# AT32F435xx_v2 register map
Vendor: Keil; Series: AT32F435; File version: 1.0
CPU: CM4 r0p1, little endian, no MPU, FPU, 4 interrupt priority bits
Registers are 32-bit, read-write, reset 0x0 unless marked. A register's access mark holds for its fields unless they carry their own. Offsets are from the block's base; [hi:lo] are bit positions; {n}, {i} and the like mark numbered series; 'fields as' and 'values as' point back to an identical list.

## TMR1 — Advanced timer
Base 0x40010000
Same registers: TMR8 0x40010400, TMR20 0x40014C00
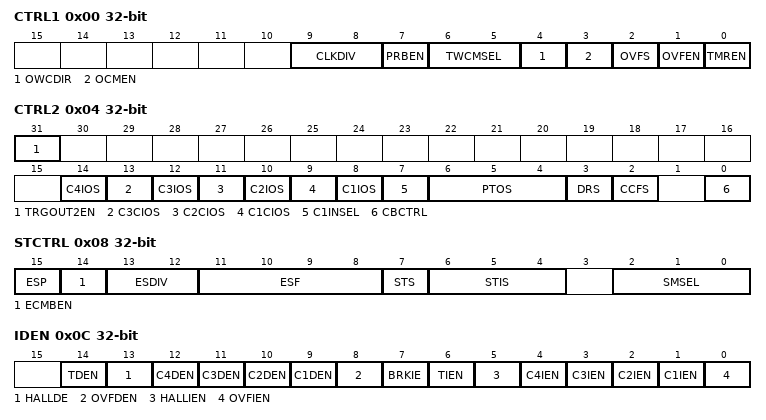
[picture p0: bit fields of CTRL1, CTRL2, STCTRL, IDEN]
0x00 CTRL1 — Control register 1
  [9:8] CLKDIV — Clock divider
  [7] PRBEN — Period buffer enable
  [6:5] TWCMSEL — Two-way count mode selection
  [4] OWCDIR — One-way count direction
  [3] OCMEN — One cycle mode enable
  [2] OVFS — Overflow event source
  [1] OVFEN — Overflow event enable
  [0] TMREN — TMR enable
0x04 CTRL2 — Control register 2
  [31] TRGOUT2EN — TRGOUT2 enable
  [2n+6] C{n}IOS (n=1..4) — Channel {n} idle output state
  [13] C3CIOS — Channel 3 complementary idle output state
  [11] C2CIOS — Channel 2 complementary idle output state
  [9] C1CIOS — Channel 1 complementary idle output state
  [7] C1INSEL — C1IN selection
  [6:4] PTOS — Primary TMR output selection
  [3] DRS — DMA request source
  [2] CCFS — Channel control bit flash select
  [0] CBCTRL — Channel buffer control
0x08 STCTRL — Subordinate TMR control register
  [15] ESP — External signal polarity
  [14] ECMBEN — External clock mode B enable
  [13:12] ESDIV — External signal divider
  [11:8] ESF — External signal filter
  [7] STS — Subordinate TMR synchronization
  [6:4] STIS — Subordinate TMR input selection
  [2:0] SMSEL — Subordinate TMR mode selection
0x0C IDEN — Interrupt/DMA enable register
  [14] TDEN — Trigger DMA request enable
  [13] HALLDE — HALL DMA request enable
  [n+8] C{n}DEN (n=1..4) — Channel {n} DMA request enable
  [8] OVFDEN — Overflow DMA request enable
  [7] BRKIE — Brake interrupt enable
  [6] TIEN — Trigger interrupt enable
  [5] HALLIEN — HALL interrupt enable
  [n] C{n}IEN (n=1..4) — Channel {n} interrupt enable
  [0] OVFIEN — Overflow interrupt enable
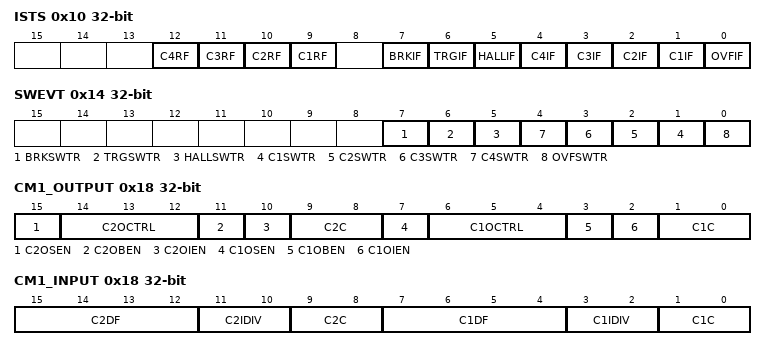
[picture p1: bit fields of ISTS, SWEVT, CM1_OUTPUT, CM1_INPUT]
0x10 ISTS — Interrupt status register
  [n+8] C{n}RF (n=1..4) — Channel {n} recapture flag
  [7] BRKIF — Brake interrupt flag
  [6] TRGIF — Trigger interrupt flag
  [5] HALLIF — HALL interrupt flag
  [n] C{n}IF (n=1..4) — Channel {n} interrupt flag
  [0] OVFIF — Overflow interrupt flag
0x14 SWEVT — Software event register
  [7] BRKSWTR — Brake event triggered by software
  [6] TRGSWTR — Trigger event triggered by software
  [5] HALLSWTR — HALL event triggered by software
  [n] C{n}SWTR (n=1..4) — Channel {n} event triggered by software
  [0] OVFSWTR — Overflow event triggered by software
0x18 CM1_OUTPUT — Channel output mode register
  [15] C2OSEN — Channel 2 output switch enable
  [14:12] C2OCTRL — Channel 2 output control
  [11] C2OBEN — Channel 2 output buffer enable
  [10] C2OIEN — Channel 2 output immediately enable
  [9:8] C2C — Channel 2 configure
  [7] C1OSEN — Channel 1 output switch enable
  [6:4] C1OCTRL — Channel 1 output control
  [3] C1OBEN — Channel 1 output buffer enable
  [2] C1OIEN — Channel 1 output immediately enable
  [1:0] C1C — Channel 1 configure
0x18 CM1_INPUT (alternate view of CM1_OUTPUT) — Channel input mode register 1
  [15:12] C2DF — Channel 2 digital filter
  [11:10] C2IDIV — Channel 2 input divider
  [9:8] C2C — Channel 2 configure
  [7:4] C1DF — Channel 1 digital filter
  [3:2] C1IDIV — Channel 1 input divider
  [1:0] C1C — Channel 1 configure
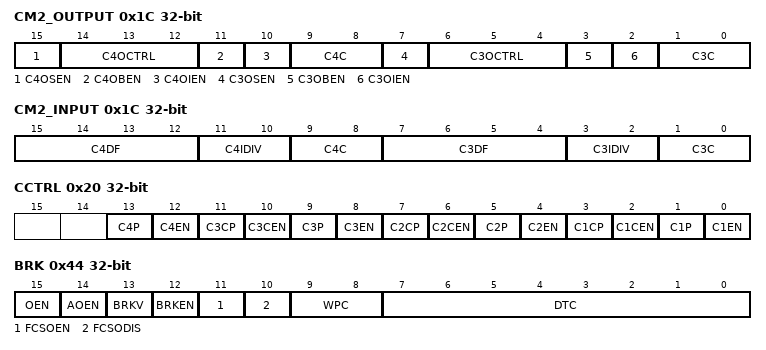
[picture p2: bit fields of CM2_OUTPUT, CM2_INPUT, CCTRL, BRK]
0x1C CM2_OUTPUT — Channel output mode register 2
  [15] C4OSEN — Channel 4 output switch enable
  [14:12] C4OCTRL — Channel 4 output control
  [11] C4OBEN — Channel 4 output buffer enable
  [10] C4OIEN — Channel 4 output immediately enable
  [9:8] C4C — Channel 4 configure
  [7] C3OSEN — Channel 3 output switch enable
  [6:4] C3OCTRL — Channel 3 output control
  [3] C3OBEN — Channel 3 output buffer enable
  [2] C3OIEN — Channel 3 output immediately enable
  [1:0] C3C — Channel 3 configure
0x1C CM2_INPUT (alternate view of CM2_OUTPUT) — Channel input mode register 2
  [15:12] C4DF — Channel 4 digital filter
  [11:10] C4IDIV — Channel 4 input divider
  [9:8] C4C — Channel 4 configure
  [7:4] C3DF — Channel 3 digital filter
  [3:2] C3IDIV — Channel 3 input divider
  [1:0] C3C — Channel 3 configure
0x20 CCTRL — Channel control register
  [4n-3] C{n}P (n=1..4) — Channel {n} Polarity
  [4n-4] C{n}EN (n=1..4) — Channel {n} enable
  [11] C3CP — Channel 3 complementary polarity
  [10] C3CEN — Channel 3 complementary enable
  [7] C2CP — Channel 2 complementary polarity
  [6] C2CEN — Channel 2 complementary enable
  [3] C1CP — Channel 1 complementary polarity
  [2] C1CEN — Channel 1 complementary enable
0x24 CVAL — Counter value
  [15:0] CVAL
0x28 DIV — Divider value
  [15:0] DIV
0x2C PR — Period value
  [15:0] PR
0x30 RPR — Repetition of period value
  [7:0] RPR
{0x30+4i} C{i}DT (i=1..4) — Channel {i} data register
  [15:0] C{i}DT
0x44 BRK — Brake register
  [15] OEN — Output enable
  [14] AOEN — Automatic output enable
  [13] BRKV — Brake input validity
  [12] BRKEN — Brake enable
  [11] FCSOEN — Frozen channel status when holistic output enable
  [10] FCSODIS — Frozen channel status when holistic output disable
  [9:8] WPC — Write protected configuration
  [7:0] DTC — Dead-time configuration
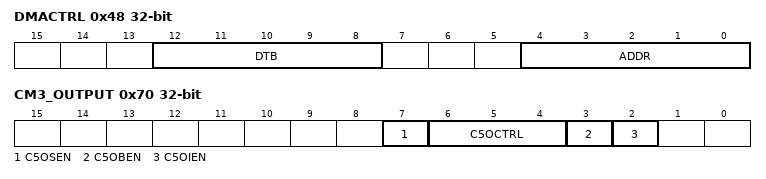
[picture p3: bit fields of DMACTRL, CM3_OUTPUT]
0x48 DMACTRL — DMA control register
  [12:8] DTB — DMA transfer bytes
  [4:0] ADDR — DMA transfer address offset
0x4C DMADT — DMA data register
  [15:0] DMADT
0x70 CM3_OUTPUT — Channel output mode register
  [7] C5OSEN — Channel 5 output switch enable
  [6:4] C5OCTRL — Channel 5 output control
  [3] C5OBEN — Channel 5 output buffer enable
  [2] C5OIEN — Channel 5 output immediately enable
0x74 C5DT — Channel 5 data register
  [15:0] C5DT

## TMR2 — General purpose timer
Base 0x40000000
Registers as TMR1, without RPR, BRK, CM3_OUTPUT, C5DT; these are added or differ:
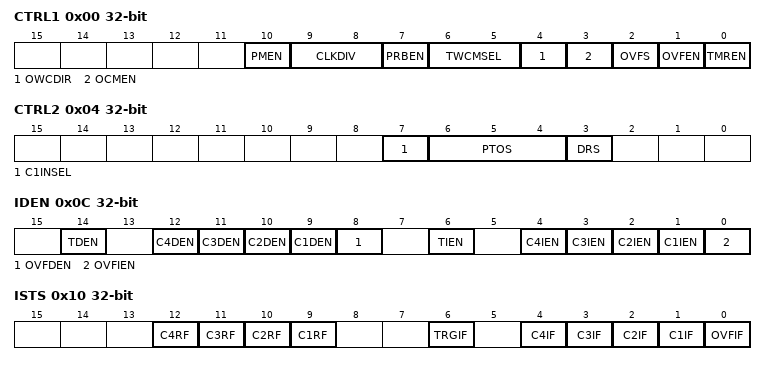
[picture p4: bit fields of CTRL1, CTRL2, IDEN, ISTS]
0x00 CTRL1 — Control register 1
  [10] PMEN — Plus Mode Enable
  [9:8] CLKDIV — Clock divider
  [7] PRBEN — Period buffer enable
  [6:5] TWCMSEL — Two-way count mode selection
  [4] OWCDIR — One-way count direction
  [3] OCMEN — One cycle mode enable
  [2] OVFS — Overflow event source
  [1] OVFEN — Overflow event enable
  [0] TMREN — TMR enable
0x04 CTRL2 — Control register 2
  [7] C1INSEL — C1IN selection
  [6:4] PTOS — Primary TMR output selection
  [3] DRS — DMA request source
0x0C IDEN — Interrupt/DMA enable register
  [14] TDEN — Trigger DMA request enable
  [n+8] C{n}DEN (n=1..4) — Channel {n} DMA request enable
  [8] OVFDEN — Overflow DMA request enable
  [6] TIEN — Trigger interrupt enable
  [n] C{n}IEN (n=1..4) — Channel {n} interrupt enable
  [0] OVFIEN — Overflow interrupt enable
0x10 ISTS — Interrupt status register
  [n+8] C{n}RF (n=1..4) — Channel {n} recapture flag
  [6] TRGIF — Trigger interrupt flag
  [n] C{n}IF (n=1..4) — Channel {n} interrupt flag
  [0] OVFIF — Overflow interrupt flag
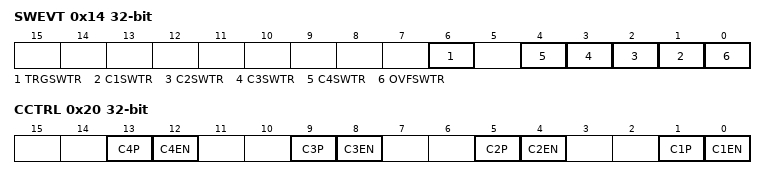
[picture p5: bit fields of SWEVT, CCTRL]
0x14 SWEVT — Software event register
  [6] TRGSWTR — Trigger event triggered by software
  [n] C{n}SWTR (n=1..4) — Channel {n} event triggered by software
  [0] OVFSWTR — Overflow event triggered by software
0x20 CCTRL — Channel control register
  [4n-3] C{n}P (n=1..4) — Channel {n} Polarity
  [4n-4] C{n}EN (n=1..4) — Channel {n} enable
0x24 CVAL — Counter value
0x2C PR — Period value
{0x30+4i} C{i}DT (i=1..4) — Channel {i} data register
0x50 TMR2_RMP — TMR2 channel input remap register
  [11:10] TMR2_CH1_IRMP — TMR2 channel 1 input remap

## TMR3 — General purpose timer
Base 0x40000400
Same registers: TMR4 0x40000800
Registers as TMR2, without TMR2_RMP; these are added or differ:
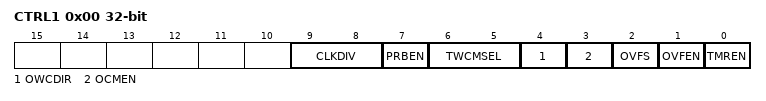
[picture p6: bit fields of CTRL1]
0x00 CTRL1 — Control register 1
  fields as TMR1.CTRL1
0x24 CVAL — Counter value
  [15:0] CVAL
0x2C PR — Period value
  [15:0] PR
{0x30+4i} C{i}DT (i=1..4) — Channel {i} data register
  [15:0] C{i}DT

## TMR5 — General purpose timer
Base 0x40000C00
Registers as TMR2 (with TMR2 read as TMR5); these are added or differ:
0x50 TMR5_RMP — TMR5 channel input remap register
  [7:6] TMR5_CH4_IRMP — TMR5 channel 4 input remap

## Notices in the file
Copyright (C) 2012-2014 ARM Limited. All rights reserved.
Purpose: System Viewer Description (SVD) Example (Schema Version 1.1)
This is a description of a none-existent and incomplete device
for demonstration purposes only.
Redistribution and use in source and binary forms, with or without
modification, are permitted provided that the following conditions are met:
- Redistributions of source code must retain the above copyright
notice, this list of conditions and the following disclaimer.
- Redistributions in binary form must reproduce the above copyright
notice, this list of conditions and the following disclaimer in the
documentation and/or other materials provided with the distribution.
- Neither the name of ARM nor the names of its contributors may be used
to endorse or promote products derived from this software without
specific prior written permission.
THIS SOFTWARE IS PROVIDED BY THE COPYRIGHT HOLDERS AND CONTRIBUTORS "AS IS"
AND ANY EXPRESS OR IMPLIED WARRANTIES, INCLUDING, BUT NOT LIMITED TO, THE
IMPLIED WARRANTIES OF MERCHANTABILITY AND FITNESS FOR A PARTICULAR PURPOSE
ARE DISCLAIMED. IN NO EVENT SHALL COPYRIGHT HOLDERS AND CONTRIBUTORS BE
LIABLE FOR ANY DIRECT, INDIRECT, INCIDENTAL, SPECIAL, EXEMPLARY, OR
CONSEQUENTIAL DAMAGES (INCLUDING, BUT NOT LIMITED TO, PROCUREMENT OF
SUBSTITUTE GOODS OR SERVICES; LOSS OF USE, DATA, OR PROFITS; OR BUSINESS
INTERRUPTION) HOWEVER CAUSED AND ON ANY THEORY OF LIABILITY, WHETHER IN
CONTRACT, STRICT LIABILITY, OR TORT (INCLUDING NEGLIGENCE OR OTHERWISE)
ARISING IN ANY WAY OUT OF THE USE OF THIS SOFTWARE, EVEN IF ADVISED OF THE
POSSIBILITY OF SUCH DAMAGE.
